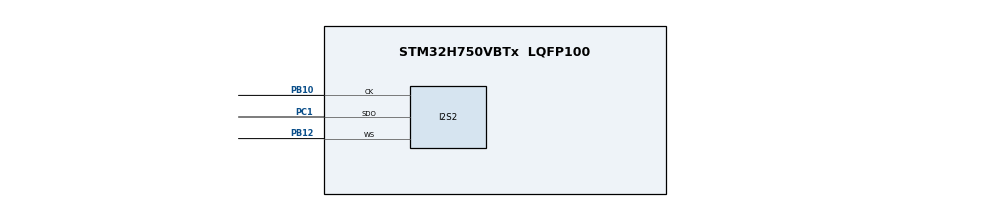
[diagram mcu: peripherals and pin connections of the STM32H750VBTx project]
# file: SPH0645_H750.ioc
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I2S2.AudioFreq=I2S_AUDIOFREQ_48K
I2S2.Data24BitAlignment=I2S_DATA_24BIT_ALIGNMENT_LEFT
I2S2.DataFormat=I2S_DATAFORMAT_24B
I2S2.ErrorAudioFreq=0.0 %
I2S2.FirstBit=I2S_FIRSTBIT_MSB
I2S2.FullDuplexMode=I2S_MODE_SLAVE_FD
I2S2.Instance=SPI$Index
I2S2.MasterKeepIOState=I2S_MASTER_KEEP_IO_STATE_ENABLE
I2S2.Mode=I2S_MODE_MASTER_RX
I2S2.RealAudioFreq=48.0 KHz
I2S2.Standard=I2S_STANDARD_PHILIPS
I2S2.VirtualMode=I2S_MODE_MASTER
Mcu.Family=STM32H7
Mcu.Name=STM32H750VBTx
Mcu.Package=LQFP100
NVIC.PriorityGroup=NVIC_PRIORITYGROUP_4
NVIC.TIM2_IRQn=true\:0\:0\:false\:false\:true\:false\:true
NVIC.TimeBase=TIM2_IRQn
NVIC.TimeBaseIP=TIM2
PA13\ (JTMS/SWDIO).Mode=Trace_Asynchronous_SW
PA13\ (JTMS/SWDIO).Signal=DEBUG_JTMS-SWDIO
PA14\ (JTCK/SWCLK).Mode=Trace_Asynchronous_SW
PA14\ (JTCK/SWCLK).Signal=DEBUG_JTCK-SWCLK
PB10.GPIO_PuPd=GPIO_NOPULL
PB10.GPIO_Speed=GPIO_SPEED_FREQ_VERY_HIGH
PB10.Mode=Half_Duplex_Master
PB10.Signal=I2S2_CK
PB12.GPIO_Speed=GPIO_SPEED_FREQ_VERY_HIGH
PB12.Mode=Half_Duplex_Master
PB12.Signal=I2S2_WS
PB3\ (JTDO/TRACESWO).Mode=Trace_Asynchronous_SW
PB3\ (JTDO/TRACESWO).Signal=DEBUG_JTDO-SWO
PC1.GPIO_Speed=GPIO_SPEED_FREQ_VERY_HIGH
PC1.Mode=Half_Duplex_Master
PC1.Signal=I2S2_SDO
PC14-OSC32_IN\ (OSC32_IN).Mode=LSE-External-Oscillator
PC14-OSC32_IN\ (OSC32_IN).Signal=RCC_OSC32_IN
PC15-OSC32_OUT\ (OSC32_OUT).Mode=LSE-External-Oscillator
PC15-OSC32_OUT\ (OSC32_OUT).Signal=RCC_OSC32_OUT
PH0-OSC_IN\ (PH0).Mode=HSE-External-Oscillator
PH0-OSC_IN\ (PH0).Signal=RCC_OSC_IN
PH1-OSC_OUT\ (PH1).Mode=HSE-External-Oscillator
PH1-OSC_OUT\ (PH1).Signal=RCC_OSC_OUT
ProjectManager.HeapSize=0x8000
ProjectManager.StackSize=0x8000
ProjectManager.TargetToolchain=Makefile
RCC.ADCFreq_Value=24768000
RCC.APB1Freq_Value=119808000
RCC.APB2Freq_Value=119808000
RCC.APB3Freq_Value=119808000
RCC.APB4Freq_Value=119808000
RCC.CortexFreq_Value=479232000
RCC.D1PPRE=RCC_APB3_DIV2
RCC.D2PPRE1=RCC_APB1_DIV2
RCC.D2PPRE2=RCC_APB2_DIV2
RCC.D3PPRE=RCC_APB4_DIV2
RCC.DIVM1=1
RCC.DIVN1=78
RCC.DIVQ1=8
RCC.HCLKFreq_Value=239616000
RCC.HPRE=RCC_HCLK_DIV2
RCC.HSE_VALUE=12288000
RCC.PLLSourceVirtual=RCC_PLLSOURCE_HSE
RCC.SYSCLKFreq_VALUE=479232000
RCC.SYSCLKSource=RCC_SYSCLKSOURCE_PLLCLK
RCC.USBCLockSelection=RCC_USBCLKSOURCE_HSI48
RCC.USBFreq_Value=48000000
VP_SYS_VS_tim2.Mode=TIM2
board=custom

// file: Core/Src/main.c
/* USER CODE BEGIN Header */
/**
  ******************************************************************************
  * @file           : main.c
  * @brief          : Main program body
  ******************************************************************************
  * @attention
  *
  * <h2><center>&copy; Copyright (c) 2021 STMicroelectronics.
  * All rights reserved.</center></h2>
  *
  * This software component is licensed by ST under BSD 3-Clause license,
  * the "License"; You may not use this file except in compliance with the
  * License. You may obtain a copy of the License at:
  *                        opensource.org/licenses/BSD-3-Clause
  *
  ******************************************************************************
  */
/* USER CODE END Header */
#include "main.h"
#include "i2s.h"
#include "gpio.h"

/* USER CODE BEGIN Includes */
#include <stdio.h>
#include "SEGGER_RTT.h"
#include "debug_helper.h"

#define HAL_TIMEOUT     1000
#define MIC_BUFF_SIZE   256

int32_t mic_buff[MIC_BUFF_SIZE];

void sph0645_test(void)
{
  HAL_StatusTypeDef hal_st;
  while(1)
  {
    hal_st = HAL_I2S_Receive(&hi2s2,
                            (uint16_t*)mic_buff,
                            MIC_BUFF_SIZE,
                            HAL_TIMEOUT);
    if(hal_st != HAL_OK)
    {
      printf("HAL_I2S hal_st=%i\n",hal_st);
      HAL_Delay(5000);
    }

    for(uint32_t i=0; i<MIC_BUFF_SIZE; i++)
    {
      printf("\nM="); printBits(sizeof(mic_buff[i]), &mic_buff[i]); HAL_Delay(10);
    }
  }
}
/* USER CODE END Includes */

void SystemClock_Config(void);

int main(void)
{

  /* MCU Configuration--------------------------------------------------------*/

  /* Reset of all peripherals, Initializes the Flash interface and the Systick. */
  HAL_Init();

  /* Configure the system clock */
  SystemClock_Config();

  /* Initialize all configured peripherals */
  MX_GPIO_Init();
  MX_I2S2_Init();
  /* USER CODE BEGIN 2 */
  SEGGER_RTT_ConfigUpBuffer(0, NULL, NULL, 0, SEGGER_RTT_MODE_NO_BLOCK_TRIM);
  //SEGGER_RTT_WriteString(0, "SEGGER RTT START\r\n\r\n");
  printf("printf ok\r\n");
  sph0645_test();
  /* USER CODE END 2 */

  /* Infinite loop */
  while (1)
  {

  }
}

void SystemClock_Config(void)
{
  RCC_OscInitTypeDef RCC_OscInitStruct = {0};
  RCC_ClkInitTypeDef RCC_ClkInitStruct = {0};

  /** Supply configuration update enable
  */
  HAL_PWREx_ConfigSupply(PWR_LDO_SUPPLY);
  /** Configure the main internal regulator output voltage
  */
  __HAL_PWR_VOLTAGESCALING_CONFIG(PWR_REGULATOR_VOLTAGE_SCALE0);

  while(!__HAL_PWR_GET_FLAG(PWR_FLAG_VOSRDY)) {}
  /** Initializes the RCC Oscillators according to the specified parameters
  * in the RCC_OscInitTypeDef structure.
  */
  RCC_OscInitStruct.OscillatorType = RCC_OSCILLATORTYPE_HSE;
  RCC_OscInitStruct.HSEState = RCC_HSE_ON;
  RCC_OscInitStruct.PLL.PLLState = RCC_PLL_ON;
  RCC_OscInitStruct.PLL.PLLSource = RCC_PLLSOURCE_HSE;
  RCC_OscInitStruct.PLL.PLLM = 1;
  RCC_OscInitStruct.PLL.PLLN = 78;
  RCC_OscInitStruct.PLL.PLLP = 2;
  RCC_OscInitStruct.PLL.PLLQ = 8;
  RCC_OscInitStruct.PLL.PLLR = 2;
  RCC_OscInitStruct.PLL.PLLRGE = RCC_PLL1VCIRANGE_3;
  RCC_OscInitStruct.PLL.PLLVCOSEL = RCC_PLL1VCOWIDE;
  RCC_OscInitStruct.PLL.PLLFRACN = 0;
  if (HAL_RCC_OscConfig(&RCC_OscInitStruct) != HAL_OK)
  {
    Error_Handler();
  }
  /** Initializes the CPU, AHB and APB buses clocks
  */
  RCC_ClkInitStruct.ClockType = RCC_CLOCKTYPE_HCLK|RCC_CLOCKTYPE_SYSCLK
                              |RCC_CLOCKTYPE_PCLK1|RCC_CLOCKTYPE_PCLK2
                              |RCC_CLOCKTYPE_D3PCLK1|RCC_CLOCKTYPE_D1PCLK1;
  RCC_ClkInitStruct.SYSCLKSource = RCC_SYSCLKSOURCE_PLLCLK;
  RCC_ClkInitStruct.SYSCLKDivider = RCC_SYSCLK_DIV1;
  RCC_ClkInitStruct.AHBCLKDivider = RCC_HCLK_DIV2;
  RCC_ClkInitStruct.APB3CLKDivider = RCC_APB3_DIV2;
  RCC_ClkInitStruct.APB1CLKDivider = RCC_APB1_DIV2;
  RCC_ClkInitStruct.APB2CLKDivider = RCC_APB2_DIV2;
  RCC_ClkInitStruct.APB4CLKDivider = RCC_APB4_DIV2;

  if (HAL_RCC_ClockConfig(&RCC_ClkInitStruct, FLASH_LATENCY_4) != HAL_OK)
  {
    Error_Handler();
  }
}

 /**
  * @brief  Period elapsed callback in non blocking mode
  * @note   This function is called  when TIM2 interrupt took place, inside
  * HAL_TIM_IRQHandler(). It makes a direct call to HAL_IncTick() to increment
  * a global variable "uwTick" used as application time base.
  * @param  htim : TIM handle
  * @retval None
  */
void HAL_TIM_PeriodElapsedCallback(TIM_HandleTypeDef *htim)
{
  if (htim->Instance == TIM2) {
    HAL_IncTick();
  }
}

void Error_Handler(void)
{
  /* USER CODE BEGIN Error_Handler_Debug */
  /* User can add his own implementation to report the HAL error return state */
  printf("Error_Handler()\n");
  HAL_Delay(100);
  __disable_irq();
  while (1)
  {
  }
  /* USER CODE END Error_Handler_Debug */
}

/************************ (C) COPYRIGHT STMicroelectronics *****END OF FILE****/
